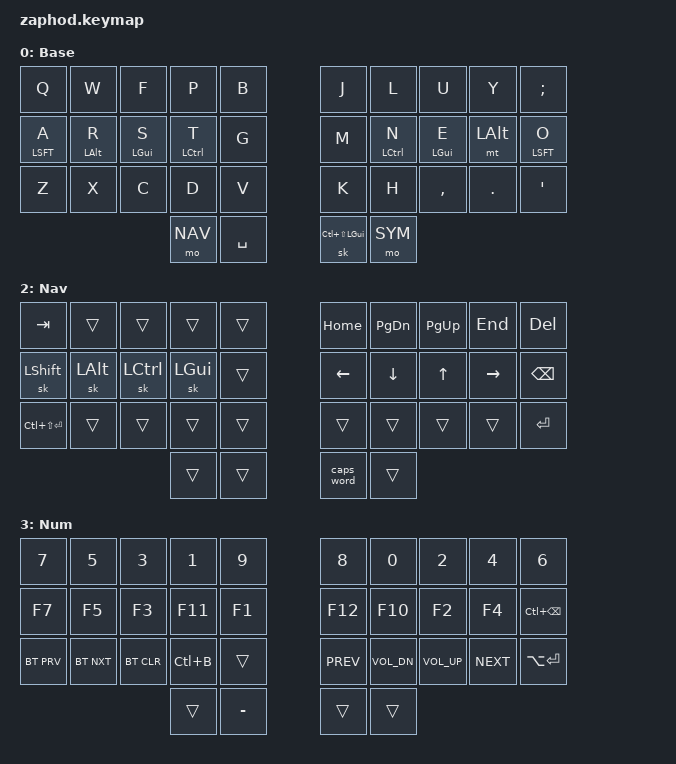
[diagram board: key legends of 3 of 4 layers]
/*
 * Copyright (c) 2021 Pete Johanson
 *
 * SPDX-License-Identifier: MIT
 */

#include <behaviors.dtsi>
#include <dt-bindings/zmk/keys.h>
#include <dt-bindings/zmk/bt.h>
#include <dt-bindings/zmk/outputs.h>

#define &kp keycode) &as LS(keycode) keycode     // Autoshift Macro

#define DEFAULT 0
#define SYM 1
#define NAV 2
#define NUM 3

// Using layer taps on thumbs, having quick tap as well helps w/ repeating space/backspace
&lt { quick_tap_ms = <200>; };
&mt { quick_tap_ms = <185>; };

/ {

    conditional_layers {
        compatible = "zmk,conditional-layers";
        tri_layer {
            if-layers = <SYM NAV>;
            then-layer = <NUM>;
        };
	
        tri_layer_other_way {
            if-layers = <NAV SYM>;
            then-layer = <NUM>;
        };
    };
    
    behaviors {
        as: auto_shift {
            compatible = "zmk,behavior-hold-tap";
            label = "AUTO_SHIFT";
            #binding-cells = <2>;
            tapping_term_ms = <185>;
            quick_tap_ms = <0>;
            flavor = "tap-preferred";
            bindings = <&kp>, <&kp>;
        };
    };

    keymap {
        compatible = "zmk,keymap";

        default_layer {
            label = "Base";
            bindings = <
                &kp Q        &kp W         &kp F         &kp P         &kp B       &kp J     &kp L         &kp U        &kp Y       &kp SEMI
                &mt LSFT A   &mt LALT R    &mt LGUI S    &mt LCTL T    &kp G       &kp M     &mt LCTL N    &mt LGUI E   &mt LALT    &mt LSFT O
                &kp Z        &kp X         &kp C         &kp D         &kp V       &kp K     &kp H         &kp COMMA    &kp DOT     &kp APOS
                                                   &mo NAV   &kp SPC     &sk LC(LS(LGUI))    &mo SYM
            >;
        };

        sym_layer {
            label = "Sym";
            bindings = <
                &kp ESC     &kp LPAR  &kp LT     &kp LBRC    &kp LBKT      &kp RBKT  &kp RBRC   &kp GT      &kp RPAR    &kp GRAVE
                &kp MINUS   &kp STAR  &kp EQUAL  &kp UNDER &kp DOLLAR      &kp AT    &sk LGUI   &sk LCTRL   &sk LALT    &sk LSHFT
                &kp PLUS    &kp PIPE  &kp TILDE  &kp SLASH &kp PERCENT     &kp POUND &kp BSLH   &kp AMPS    &kp QMARK   &kp EXCL                                                   &kp LS(N0) &kp UNDER         &trans &trans
                                                 &trans    &key_repeat     &trans    &trans
	    >;
        };
	
        nav_layer {
            label = "Nav";
            bindings = <
                &kp TAB    &trans     &trans      &trans          &trans       &kp HOME         &kp PG_DN      &kp PG_UP  &kp END     &kp DEL
                &sk LSHFT  &sk LALT   &sk LCTRL   &sk LGUI        &trans       &kp LEFT         &kp DOWN       &kp UP     &kp RIGHT   &kp BSPC
                &kp LC(LS(RET)) &trans &trans     &trans          &trans       &trans           &trans         &trans     &trans      &kp RET
                                                  &trans          &trans       &caps_word       &trans
            >;
        };

        num_layer {
            label = "Num";
            bindings = <
                &kp N7     &kp N5     &kp N3          &kp N1          &kp N9        &kp N8          &kp N0         &kp N2     &kp N4      &kp N6
                &kp F7     &kp F5     &kp F3          &kp F11         &kp F1        &kp F12         &kp F10        &kp F2     &kp F4      &kp LC(BSPC)
                &bt BT_PRV &bt BT_NXT &bt BT_CLR      &kp LC(B)       &trans        &kp K_PREV      &kp K_VOL_DN   &kp K_VOL_UP  &kp K_NEXT  &kp LA(RET)
                                                      &trans         &kp MINUS     &trans          &trans
            >;
        };
   };
};

